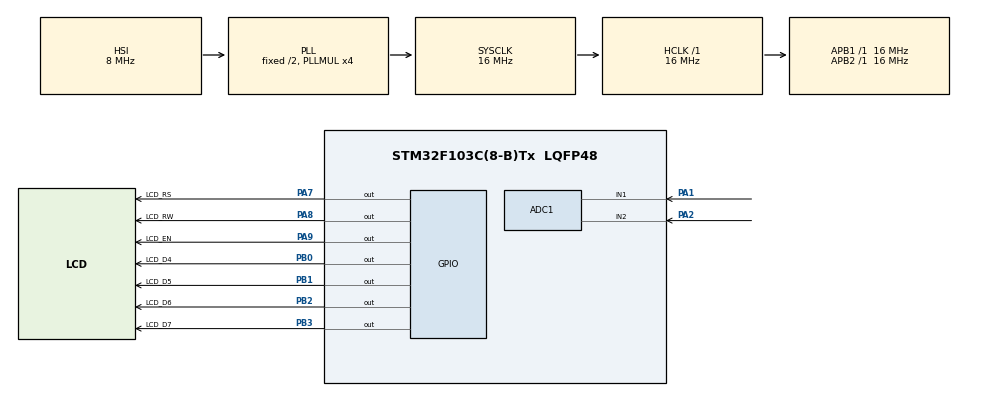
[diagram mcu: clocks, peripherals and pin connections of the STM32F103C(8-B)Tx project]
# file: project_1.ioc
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ADC1.Channel-0\#ChannelRegularConversion=ADC_CHANNEL_1
ADC1.Channel-1\#ChannelRegularConversion=ADC_CHANNEL_2
ADC1.DiscontinuousConvMode=ENABLE
ADC1.ExternalTrigConv=ADC_EXTERNALTRIGCONV_T1_CC1
ADC1.NbrOfConversion=2
ADC1.NbrOfConversionFlag=1
ADC1.NbrOfDiscConversion=2
ADC1.Rank-0\#ChannelRegularConversion=1
ADC1.Rank-1\#ChannelRegularConversion=2
ADC1.SamplingTime-0\#ChannelRegularConversion=ADC_SAMPLETIME_1CYCLE_5
ADC1.SamplingTime-1\#ChannelRegularConversion=ADC_SAMPLETIME_1CYCLE_5
ADC1.master=1
Dma.ADC1.0.Direction=DMA_PERIPH_TO_MEMORY
Dma.ADC1.0.Instance=DMA1_Channel1
Dma.ADC1.0.MemDataAlignment=DMA_MDATAALIGN_WORD
Dma.ADC1.0.MemInc=DMA_MINC_ENABLE
Dma.ADC1.0.Mode=DMA_CIRCULAR
Dma.ADC1.0.PeriphDataAlignment=DMA_PDATAALIGN_WORD
Dma.ADC1.0.PeriphInc=DMA_PINC_DISABLE
Dma.ADC1.0.Priority=DMA_PRIORITY_LOW
Dma.Request0=ADC1
Mcu.Family=STM32F1
Mcu.Name=STM32F103C(8-B)Tx
Mcu.Package=LQFP48
NVIC.DMA1_Channel1_IRQn=true\:0\:0\:false\:false\:true\:false\:true\:true
NVIC.PriorityGroup=NVIC_PRIORITYGROUP_4
PA1.Signal=ADCx_IN1
PA2.Signal=ADCx_IN2
PA7.GPIO_Label=LCD_RS
PA7.GPIO_Speed=GPIO_SPEED_FREQ_HIGH
PA7.Signal=GPIO_Output
PA8.GPIO_Label=LCD_RW
PA8.GPIO_Speed=GPIO_SPEED_FREQ_HIGH
PA8.Signal=GPIO_Output
PA9.GPIO_Label=LCD_EN
PA9.Signal=GPIO_Output
PB0.GPIO_Label=LCD_D4
PB0.GPIO_Speed=GPIO_SPEED_FREQ_HIGH
PB0.Signal=GPIO_Output
PB1.GPIO_Label=LCD_D5
PB1.GPIO_Speed=GPIO_SPEED_FREQ_HIGH
PB1.Signal=GPIO_Output
PB2.GPIO_Label=LCD_D6
PB2.GPIO_Speed=GPIO_SPEED_FREQ_HIGH
PB2.Signal=GPIO_Output
PB3.GPIO_Label=LCD_D7
PB3.GPIO_Speed=GPIO_SPEED_FREQ_HIGH
PB3.Signal=GPIO_Output
ProjectManager.HeapSize=0x200
ProjectManager.StackSize=0x400
ProjectManager.TargetToolchain=Makefile
RCC.AHBFreq_Value=16000000
RCC.APB1Freq_Value=16000000
RCC.APB1TimFreq_Value=16000000
RCC.APB2Freq_Value=16000000
RCC.APB2TimFreq_Value=16000000
RCC.HCLKFreq_Value=16000000
RCC.PLLMUL=RCC_PLL_MUL4
RCC.SYSCLKFreq_VALUE=16000000
RCC.SYSCLKSource=RCC_SYSCLKSOURCE_PLLCLK
RCC.USBFreq_Value=16000000
SH.ADCx_IN1.0=ADC1_IN1,IN1
SH.ADCx_IN2.0=ADC1_IN2,IN2
TIM3.Channel-PWM\ Generation4\ No\ Output=TIM_CHANNEL_4
TIM4.Prescaler=15
VP_SYS_VS_ND.Mode=No_Debug
VP_TIM3_VS_ClockSourceINT.Mode=Internal
VP_TIM3_VS_no_output4.Mode=PWM Generation4 No Output
VP_TIM4_VS_ClockSourceINT.Mode=Internal
board=custom

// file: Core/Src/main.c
/* USER CODE BEGIN Header */
/**
  ******************************************************************************
  * @file           : main.c
  * @brief          : Main program body
  ******************************************************************************
  * @attention
  *
  * Copyright (c) 2025 STMicroelectronics.
  * All rights reserved.
  *
  * This software is licensed under terms that can be found in the LICENSE file
  * in the root directory of this software component.
  * If no LICENSE file comes with this software, it is provided AS-IS.
  *
  ******************************************************************************
  */
/* USER CODE END Header */
#include "main.h"
#include "adc.h"
#include "dma.h"
#include "tim.h"
#include "gpio.h"

/* USER CODE BEGIN Includes */
#include "delay_hardware.h"
#include "lcd.h"
/* USER CODE END Includes */

void SystemClock_Config(void);

int main(void)
{

  /* MCU Configuration--------------------------------------------------------*/

  /* Reset of all peripherals, Initializes the Flash interface and the Systick. */
  HAL_Init();

  /* Configure the system clock */
  SystemClock_Config();

  /* Initialize all configured peripherals */
	MX_GPIO_Init();
	MX_DMA_Init();
	MX_ADC1_Init();
	MX_TIM3_Init();
	MX_TIM4_Init();
	/* USER CODE BEGIN 2 */
	delay_hardware_init_ex();
	lcd_init();
	lcd_gotoxy(1, 0);
	lcd_puts("NGUYEN VAN LOC");
	lcd_gotoxy(5, 1);
	lcd_puts("SELEX");
  /* USER CODE END 2 */
  /* Infinite loop */
  while (1)
  {
//		LL_GPIO_SetOutputPin(LCD_D6_GPIO_Port, LCD_D7_Pin);

  }
}

void SystemClock_Config(void)
{
  RCC_OscInitTypeDef RCC_OscInitStruct = {0};
  RCC_ClkInitTypeDef RCC_ClkInitStruct = {0};
  RCC_PeriphCLKInitTypeDef PeriphClkInit = {0};

  /** Initializes the RCC Oscillators according to the specified parameters
  * in the RCC_OscInitTypeDef structure.
  */
  RCC_OscInitStruct.OscillatorType = RCC_OSCILLATORTYPE_HSI;
  RCC_OscInitStruct.HSIState = RCC_HSI_ON;
  RCC_OscInitStruct.HSICalibrationValue = RCC_HSICALIBRATION_DEFAULT;
  RCC_OscInitStruct.PLL.PLLState = RCC_PLL_ON;
  RCC_OscInitStruct.PLL.PLLSource = RCC_PLLSOURCE_HSI_DIV2;
  RCC_OscInitStruct.PLL.PLLMUL = RCC_PLL_MUL4;
  if (HAL_RCC_OscConfig(&RCC_OscInitStruct) != HAL_OK)
  {
    Error_Handler();
  }

  /** Initializes the CPU, AHB and APB buses clocks
  */
  RCC_ClkInitStruct.ClockType = RCC_CLOCKTYPE_HCLK|RCC_CLOCKTYPE_SYSCLK
                              |RCC_CLOCKTYPE_PCLK1|RCC_CLOCKTYPE_PCLK2;
  RCC_ClkInitStruct.SYSCLKSource = RCC_SYSCLKSOURCE_PLLCLK;
  RCC_ClkInitStruct.AHBCLKDivider = RCC_SYSCLK_DIV1;
  RCC_ClkInitStruct.APB1CLKDivider = RCC_HCLK_DIV1;
  RCC_ClkInitStruct.APB2CLKDivider = RCC_HCLK_DIV1;

  if (HAL_RCC_ClockConfig(&RCC_ClkInitStruct, FLASH_LATENCY_0) != HAL_OK)
  {
    Error_Handler();
  }
  PeriphClkInit.PeriphClockSelection = RCC_PERIPHCLK_ADC;
  PeriphClkInit.AdcClockSelection = RCC_ADCPCLK2_DIV2;
  if (HAL_RCCEx_PeriphCLKConfig(&PeriphClkInit) != HAL_OK)
  {
    Error_Handler();
  }
}

void Error_Handler(void)
{
  __disable_irq();
  while (1)
  {
  }
}
